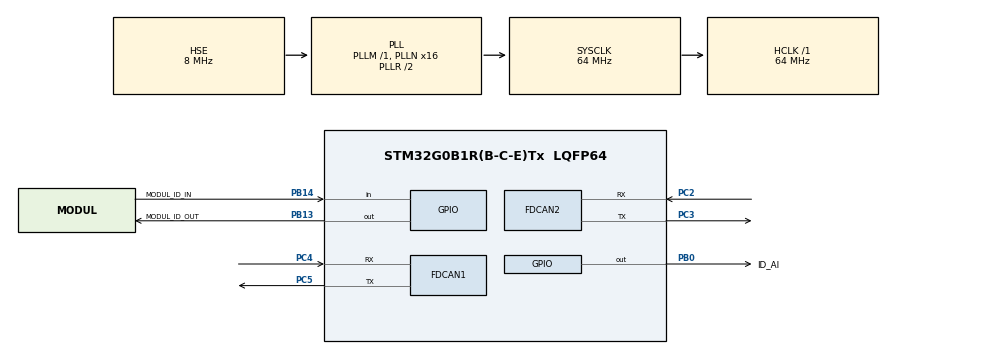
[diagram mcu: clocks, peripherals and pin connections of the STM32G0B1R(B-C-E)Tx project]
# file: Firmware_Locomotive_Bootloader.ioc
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FDCAN1.AutoRetransmission=ENABLE
FDCAN1.CalculateBaudRateNominal=50000
FDCAN1.CalculateTimeBitNominal=20000
FDCAN1.CalculateTimeQuantumNominal=2500.0
FDCAN1.NominalPrescaler=160
FDCAN1.NominalTimeSeg1=5
FDCAN1.NominalTimeSeg2=2
FDCAN2.AutoRetransmission=ENABLE
FDCAN2.CalculateBaudRateNominal=50000
FDCAN2.CalculateTimeBitNominal=20000
FDCAN2.CalculateTimeQuantumNominal=2500.0
FDCAN2.NominalPrescaler=160
FDCAN2.NominalTimeSeg1=5
FDCAN2.NominalTimeSeg2=2
Mcu.Family=STM32G0
Mcu.Name=STM32G0B1R(B-C-E)Tx
Mcu.Package=LQFP64
NVIC.TIM16_FDCAN_IT0_IRQn=true\:0\:0\:false\:false\:true\:true\:true\:true
NVIC.TIM17_FDCAN_IT1_IRQn=true\:0\:0\:false\:false\:true\:true\:true\:true
PA13.Mode=Serial_Wire
PA13.Signal=SYS_SWDIO
PA14-BOOT0.Mode=Serial_Wire
PA14-BOOT0.Signal=SYS_SWCLK
PB0.GPIO_Label=ID_AI
PB0.Signal=GPIO_Output
PB13.GPIO_Label=MODUL_ID_OUT
PB13.Signal=GPIO_Output
PB14.GPIO_Label=MODUL_ID_IN
PB14.Signal=GPIO_Input
PC2.GPIO_Speed=GPIO_SPEED_FREQ_VERY_HIGH
PC2.Mode=FDCAN_Activate
PC2.Signal=FDCAN2_RX
PC3.GPIO_Speed=GPIO_SPEED_FREQ_VERY_HIGH
PC3.Mode=FDCAN_Activate
PC3.Signal=FDCAN2_TX
PC4.GPIO_Speed=GPIO_SPEED_FREQ_VERY_HIGH
PC4.Mode=FDCAN_Activate
PC4.PinState=GPIO_PIN_RESET
PC4.Signal=FDCAN1_RX
PC5.GPIO_Speed=GPIO_SPEED_FREQ_VERY_HIGH
PC5.Mode=FDCAN_Activate
PC5.Signal=FDCAN1_TX
PF0-OSC_IN\ (PF0).Mode=HSE-External-Oscillator
PF0-OSC_IN\ (PF0).Signal=RCC_OSC_IN
PF1-OSC_OUT\ (PF1).Mode=HSE-External-Oscillator
PF1-OSC_OUT\ (PF1).Signal=RCC_OSC_OUT
ProjectManager.HeapSize=0x200
ProjectManager.StackSize=0x400
ProjectManager.TargetToolchain=STM32CubeIDE
RCC.ADCFreq_Value=64000000
RCC.AHBFreq_Value=64000000
RCC.CortexFreq_Value=64000000
RCC.EXTERNAL_CLOCK_VALUE=48000
RCC.HCLKFreq_Value=64000000
RCC.HSE_VALUE=8000000
RCC.HSI48_VALUE=48000000
RCC.HSI_VALUE=16000000
RCC.LSE_VALUE=32768
RCC.PLLN=16
RCC.PLLSourceVirtual=RCC_PLLSOURCE_HSE
RCC.SYSCLKFreq_VALUE=64000000
RCC.SYSCLKSource=RCC_SYSCLKSOURCE_PLLCLK
RCC.USBFreq_Value=48000000
RCC.VCOOutputFreq_Value=128000000
VP_SYS_VS_DBSignals.Mode=DisableDeadBatterySignals
board=custom

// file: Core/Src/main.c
/* USER CODE BEGIN Header */
/**
  ******************************************************************************
  * @file           : main.c
  * @brief          : Main program body
  ******************************************************************************
  * @attention
  *
  * Copyright (c) 2026 STMicroelectronics.
  * All rights reserved.
  *
  * This software is licensed under terms that can be found in the LICENSE file
  * in the root directory of this software component.
  * If no LICENSE file comes with this software, it is provided AS-IS.
  *
  ******************************************************************************
  */
/* USER CODE END Header */
#include "main.h"
#include "fdcan.h"
#include "gpio.h"

/* USER CODE BEGIN Includes */
#include "boot_core/stm32g0/boot_core.h"
/* USER CODE END Includes */

/* USER CODE BEGIN PV */
extern FDCAN_HandleTypeDef hfdcan2;
/* USER CODE END PV */

void SystemClock_Config(void);

int main(void)
{

  /* MCU Configuration--------------------------------------------------------*/

  /* Reset of all peripherals, Initializes the Flash interface and the Systick. */
  HAL_Init();

  /* Configure the system clock */
  SystemClock_Config();

  /* Initialize all configured peripherals */
  MX_GPIO_Init();
  MX_FDCAN1_Init();
  MX_FDCAN2_Init();
  /* USER CODE BEGIN 2 */
  /* CAN2 (PC2/PC3) is the bus to the Main PLC. Never returns. */
  Boot_Run(&hfdcan2);
  /* USER CODE END 2 */

  /* Infinite loop */
  while (1)
  {

  }
}

void SystemClock_Config(void)
{
  RCC_OscInitTypeDef RCC_OscInitStruct = {0};
  RCC_ClkInitTypeDef RCC_ClkInitStruct = {0};

  /** Configure the main internal regulator output voltage
  */
  HAL_PWREx_ControlVoltageScaling(PWR_REGULATOR_VOLTAGE_SCALE1);

  /** Initializes the RCC Oscillators according to the specified parameters
  * in the RCC_OscInitTypeDef structure.
  */
  RCC_OscInitStruct.OscillatorType = RCC_OSCILLATORTYPE_HSE;
  RCC_OscInitStruct.HSEState = RCC_HSE_ON;
  RCC_OscInitStruct.PLL.PLLState = RCC_PLL_ON;
  RCC_OscInitStruct.PLL.PLLSource = RCC_PLLSOURCE_HSE;
  RCC_OscInitStruct.PLL.PLLM = RCC_PLLM_DIV1;
  RCC_OscInitStruct.PLL.PLLN = 16;
  RCC_OscInitStruct.PLL.PLLP = RCC_PLLP_DIV2;
  RCC_OscInitStruct.PLL.PLLQ = RCC_PLLQ_DIV2;
  RCC_OscInitStruct.PLL.PLLR = RCC_PLLR_DIV2;
  if (HAL_RCC_OscConfig(&RCC_OscInitStruct) != HAL_OK)
  {
    Error_Handler();
  }

  /** Initializes the CPU, AHB and APB buses clocks
  */
  RCC_ClkInitStruct.ClockType = RCC_CLOCKTYPE_HCLK|RCC_CLOCKTYPE_SYSCLK
                              |RCC_CLOCKTYPE_PCLK1;
  RCC_ClkInitStruct.SYSCLKSource = RCC_SYSCLKSOURCE_PLLCLK;
  RCC_ClkInitStruct.AHBCLKDivider = RCC_SYSCLK_DIV1;
  RCC_ClkInitStruct.APB1CLKDivider = RCC_HCLK_DIV1;

  if (HAL_RCC_ClockConfig(&RCC_ClkInitStruct, FLASH_LATENCY_2) != HAL_OK)
  {
    Error_Handler();
  }
}

void Error_Handler(void)
{
  __disable_irq();
  while (1)
  {
  }
}
